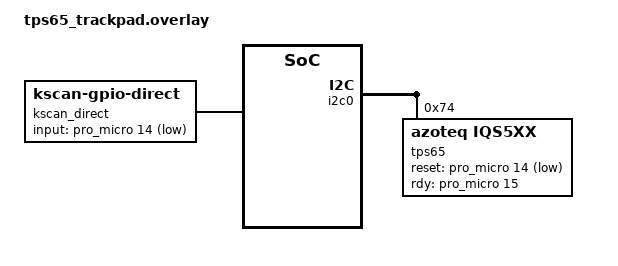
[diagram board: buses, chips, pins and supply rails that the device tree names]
#include <dt-bindings/zmk/matrix_transform.h>

/ {
    chosen {
        zmk,kscan = &kscan_direct;
        zmk,matrix-transform = &default_transform;
    };

    kscan_direct: kscan_direct {
        compatible = "zmk,kscan-gpio-direct";
        wakeup-source;

        input-gpios
            = <&pro_micro 14 (GPIO_ACTIVE_LOW | GPIO_PULL_UP)>;
    };

    default_transform: keymap_transform_0 {
        compatible = "zmk,matrix-transform";
        columns = <1>;
        rows = <1>;
        map = <RC(0,0)>;
    };

    tps65_input: tps65_input {
        compatible = "zmk,input-listener";
        device = <&tps65>;
    };
};

&i2c0 {
    status = "okay";

    tps65: iqs5xx@74 {
        status = "okay";
        compatible = "azoteq,iqs5xx";
        reg = <0x74>;

        one-finger-tap;
        press-and-hold;
        press-and-hold-time = <250>;
        two-finger-tap;

        scroll;
        natural-scroll-y;
        natural-scroll-x;

        bottom-beta = <5>;
        stationary-threshold = <5>;

        switch-xy;

        reset-gpios = <&pro_micro 14 GPIO_ACTIVE_LOW>;
        rdy-gpios = <&pro_micro 15 GPIO_ACTIVE_HIGH>;
    };
};
